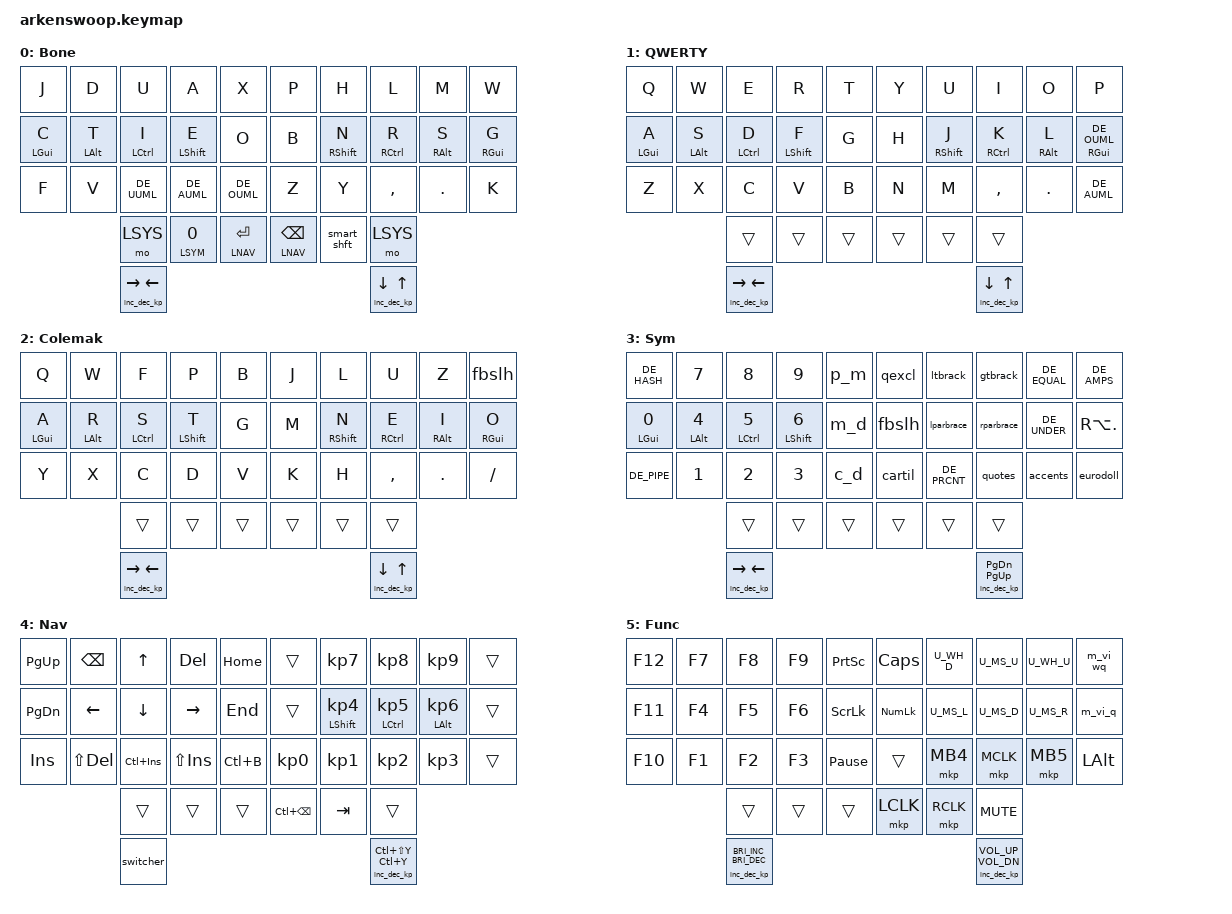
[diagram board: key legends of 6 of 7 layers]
/*
 * Copyright (c) 2023 The ZMK Contributors
 *
 * SPDX-License-Identifier: MIT
 */


#include <behaviors.dtsi>
#include "zmk-helpers/helper.h"
#include "zmk-helpers/key-labels/36.h"
#include <dt-bindings/zmk/keys.h>
#include <dt-bindings/zmk/ext_power.h>
#include <dt-bindings/zmk/outputs.h>
#include "keys_de.h"
#include <dt-bindings/zmk/bt.h>
#include <behaviors/num_word.dtsi>
#include "mouse.dtsi"
#include "arkenswoop_combos.dtsi"
#if __has_include("extras-arkenswoop.dtsi")
#include "extras-arkenswoop.dtsi"
#endif

#define ________ &trans
#define __XXXX__ &none

#define DE_AUML DE_A_UMLAUT
#define DE_OUML DE_O_UMLAUT
#define DE_UUML DE_U_UMLAUT

#define LBONE 0
#define LQWERTY 1 
#define LCOLMK 2
#define LSYM 3
#define LNAV 4
#define LFN  5
#define LSYS 6


/* Global settings */

#define QUICK_TAP_MS 175

&sk {  // sticky-key config
    release-after-ms = <900>;  // release after 0.9s
    quick-release;             // no double capitalization when rolling keys
};

&sl {  // sticky-layer config
    ignore-modifiers;          // allow chording sticky mods & layers
};

&lt {  // layer-tap config
    flavor = "balanced";
    tapping-term-ms = <200>;
    quick-tap-ms = <QUICK_TAP_MS>;
};

&key_repeat {
    usage-pages = <HID_USAGE_KEY HID_USAGE_CONSUMER>;
};


/* Homerow mods */

#define KEYS_L LT0 LT1 LT2 LT3 LT4 LM0 LM1 LM2 LM3 LM4 LB0 LB1 LB2 LB3 LB4 // left hand
#define KEYS_R RT0 RT1 RT2 RT3 RT4 RM0 RM1 RM2 RM3 RM4 RB0 RB1 RB2 RB3 RB4 // right hand
#define THUMBS LH2 LH1 LH0 RH0 RH1 RH2                // thumbs

#define MAKE_HRM(NAME, HOLD, TAP, TRIGGER_POS) \
    ZMK_BEHAVIOR(NAME, hold_tap, \
        flavor = "balanced"; \
        tapping-term-ms = <280>; \
        quick-tap-ms = <QUICK_TAP_MS>; \
        require-prior-idle-ms = <200>; \
        bindings = <HOLD>, <TAP>; \
        hold-trigger-key-positions = <TRIGGER_POS>; \
        hold-trigger-on-release; \
    )
MAKE_HRM(hml, &kp, &kp, KEYS_R THUMBS)  // left-hand HRMs
MAKE_HRM(hmr, &kp, &kp, KEYS_L THUMBS)  // right-hand HRMs



/* Caps-word, num-word and smart-mouse */

&caps_word {
    continue-list = <UNDERSCORE MINUS>;
};
// tap: sticky-shift | shift + tap/ double-tap: caps-word | hold: shift
ZMK_BEHAVIOR(smart_shft, mod_morph,
    bindings = <&sk LSHFT>, <&caps_word>;
    mods = <(MOD_LSFT)>;
)

// tap: space | shift + tap: dot -> space -> sticky shift | hold: activate layer
ZMK_BEHAVIOR(lt_spc, hold_tap,
    flavor = "balanced";
    tapping-term-ms = <200>;
    quick-tap-ms = <QUICK_TAP_MS>;
    bindings = <&mo>, <&spc_morph>;
)
ZMK_BEHAVIOR(spc_morph, mod_morph,
    bindings = <&kp SPACE>, <&dot_spc>;
    mods = <(MOD_LSFT|MOD_RSFT)>;
)
ZMK_BEHAVIOR(dot_spc, macro,
    wait-ms = <0>;
    tap-ms = <5>;
    bindings = <&kp DOT &kp SPACE &sk LSHFT>;
)

ZMK_TAP_DANCE(td_s,
    bindings = <&kp N1>, <&kp N2>, <&kp N3>;
)
// tap: num-word | double-tap: sticky num-layer | hold: num-layer

#define SMART_NUM &smart_num SYM 0
ZMK_BEHAVIOR(smart_num, hold_tap,
    flavor = "balanced";
    tapping-term-ms = <200>;
    quick-tap-ms = <QUICK_TAP_MS>;
    bindings = <&mo>, <&num_dance>;
)
ZMK_BEHAVIOR(num_dance, tap_dance,
    tapping-term-ms = <200>;
    bindings = <&num_word LSYM>, <&sl LSYM>;  // reverse this for sticky-num on single tap
)
&num_word {
    continue-list = <BSPC DEL DOT COMMA DE_PLUS DE_MINUS DE_STAR DE_FSLH LS(N0)>;
    ignore-modifiers;     
};


/* BLUETOOTH MACROS */
ZMK_BEHAVIOR(m_bt_sel, macro_one_param,
    wait-ms = <0>;
    tap-ms = <0>;
    bindings
      = <&macro_param_1to2>
      , <&bt BT_SEL MACRO_PLACEHOLDER>
      ;
)

ZMK_BEHAVIOR(m_bt_clr_prof, macro_one_param,
    wait-ms = <0>;
    tap-ms = <0>;
    bindings
      = <&macro_param_1to1>
      , <&m_bt_sel MACRO_PLACEHOLDER>
      , <&bt BT_CLR>
    ;
)

ZMK_BEHAVIOR(ht_btp, hold_tap,
    flavor = "tap-preferred";
    tapping-term-ms = <3000>;
    bindings = <&m_bt_clr_prof>,<&m_bt_sel>;
)

/* SYMBOLS */

// + or * (with SHFT)
ZMK_BEHAVIOR(p_m, mod_morph,
    bindings = <&kp DE_PLUS>, <&kp DE_STAR>;
    mods = <(MOD_LSFT|MOD_RSFT)>;
)

// - or / (with SHFT)
ZMK_BEHAVIOR(m_d, mod_morph,
    bindings = <&kp DE_MINUS>, <&kp DE_FSLH>;
    mods = <(MOD_LSFT|MOD_RSFT)>;
)
// , or . (with SHFT)
ZMK_BEHAVIOR(c_d, mod_morph,
    bindings = <&kp COMMA>, <&kp DOT>;
    mods = <(MOD_LSFT|MOD_RSFT)>;
)
// ( and { (with SHFT)
ZMK_BEHAVIOR(lparbrace, mod_morph,
    bindings = <&kp DE_LEFT_PARENTHESIS>, <&kp DE_LEFT_BRACE>;
    mods = <(MOD_LSFT|MOD_RSFT)>;
)
// ) and } (with SHFT)
ZMK_BEHAVIOR(rparbrace, mod_morph,
    bindings = <&kp DE_RIGHT_PARENTHESIS>, <&kp DE_RIGHT_BRACE>;
    mods = <(MOD_LSFT|MOD_RSFT)>;
)
// < and [ (with SHFT)
ZMK_BEHAVIOR(ltbrack, mod_morph,
    bindings = <&kp DE_LESS_THAN>, <&kp DE_LEFT_BRACKET>;
    mods = <(MOD_LSFT|MOD_RSFT)>;
)
// > and ] (with SHFT)
ZMK_BEHAVIOR(gtbrack, mod_morph,
    bindings = <&kp DE_GREATER_THAN>, <&kp DE_RIGHT_BRACKET>;
    mods = <(MOD_LSFT|MOD_RSFT)>;
)
// ' and " (with SHFT)
ZMK_BEHAVIOR(quotes, mod_morph,
    bindings = <&kp DE_SQT>, <&kp DE_DQT>;
    mods = <(MOD_LSFT|MOD_RSFT)>;
)
// ´ and ` (with SHFT)
ZMK_BEHAVIOR(accents, mod_morph,
    bindings = <&kp DE_ACUTE>, <&kp DE_GRAVE>;
    mods = <(MOD_LSFT|MOD_RSFT)>;
)
// ? and ! (with SHFT)
ZMK_BEHAVIOR(qexcl, mod_morph,
    bindings = <&kp DE_QMARK>, <&kp DE_EXCL>;
    mods = <(MOD_LSFT|MOD_RSFT)>;
)
// $ and € (with SHFT)
ZMK_BEHAVIOR(eurodoll, mod_morph,
    bindings = <&kp DE_DOLLAR>, <&kp DE_EURO>;
    mods = <(MOD_LSFT|MOD_RSFT)>;
)
// / and \ (with SHFT) 
ZMK_BEHAVIOR(fbslh, mod_morph,
    bindings = <&kp DE_FSLH>, <&kp DE_BSLH>;
    mods = <(MOD_LSFT|MOD_RSFT)>;
)
// ß and  (with SHFT)  
ZMK_BEHAVIOR(sz, mod_morph,
    bindings = <&kp DE_SZ>, <&kp DE_CAPITAL_SZ>;
    mods = <(MOD_LSFT|MOD_RSFT)>;
)
// ^ and ~ (with SHFT)  
ZMK_BEHAVIOR(cartil, mod_morph,
    bindings = <&kp DE_CARET>, <&kp DE_TILDE>;
    mods = <(MOD_LSFT|MOD_RSFT)>;
)

// Copy
// Ctrl+C or Ctrl+Ins  (with SHFT)  
ZMK_BEHAVIOR(copy, mod_morph,
    bindings = <&kp LC(C)>, <&kp LC(INS)>;
    mods = <(MOD_LSFT|MOD_RSFT)>;
)
// Paste
// Ctrl+V or Shft+Ins  (with SHFT)  
ZMK_BEHAVIOR(paste, mod_morph,
    bindings = <&kp LC(V)>, <&kp LS(INS)>;
    mods = <(MOD_LSFT|MOD_RSFT)>;
)


/* Switcher encoder */
/* Encoder switches windows */
/ {
    behaviors {
        switcher: switcher {
            compatible = "zmk,behavior-sensor-rotate";
            label = "ENCODER_SW";
            #sensor-binding-cells = <0>;
            bindings = <&alttab>, <&alttab_p>;
        };
};
};
ZMK_BEHAVIOR(alttab, tri_state, bindings = <&kp LALT>, <&kp TAB>, <&kt LALT>; )
ZMK_BEHAVIOR(alttab_p, tri_state, bindings = <&kp LALT>, <&kp LS(TAB)>, <&kt LALT>; )

ZMK_BEHAVIOR(m_vi_wq, macro, wait-ms = <50>; bindings = <&kp ESC &kp DE_COLON &kp W &kp Q>; )
ZMK_BEHAVIOR(m_vi_q, macro, wait-ms = <50>; bindings = <&kp ESC &kp DE_COLON &kp Q &kp DE_EXCL>; )


ZMK_CONDITIONAL_LAYER(fnlay, LSYM LNAV, LFN)

ZMK_LAYER(Bone,
    // ╭─────────────┬─────────────┬─────────────┬─────────────┬─────────────╮    ╭─────────────┬─────────────┬─────────────┬─────────────┬─────────────╮
         &kp J         &kp D         &kp U         &kp A         &kp X              &kp P         &kp H         &kp L         &kp M         &kp W       
    // ├─────────────┼─────────────┼─────────────┼─────────────┼─────────────┤    ├─────────────┼─────────────┼─────────────┼─────────────┼─────────────┤
         &hml LGUI C   &hml LALT T   &hml LCTRL I  &hml LSHFT E  &kp O              &kp B         &hmr RSHFT N  &hmr RCTRL R  &hmr RALT S   &hmr RGUI G 
    // ├─────────────┼─────────────┼───── ü ─────┼───── ä ─────┼───── ö ─────┤    ├─────────────┬─────────────┼─────────────┼─────────────┼─────────────┤
         &kp F         &kp V         &kp DE_UUML   &kp DE_AUML   &kp DE_OUML        &kp Z         &kp Y         &kp COMMA     &kp DOT       &kp K       
    // ╰─────────────┼─────────────┼─────────────┼─────────────┼─────────────┤    ├─────────────┬─────────────┼─────────────┼─────────────┼─────────────╯
                                     &mo LSYS      &lt_spc LSYM 0 &lt LNAV RET      &lt LNAV BSPC &smart_shft   &mo LSYS
    //                             ╰─────────────┴─────────────┴─────────────╯    ╰─────────────┴─────────────┴─────────────╯
    ,                            &inc_dec_kp RIGHT LEFT                                                     &inc_dec_kp DOWN UP                        
    //                                (       )                                                                  (       )
)

ZMK_LAYER(QWERTY,
    // ╭─────────────┬─────────────┬─────────────┬─────────────┬─────────────╮    ╭─────────────┬─────────────┬─────────────┬─────────────┬─────────────╮
         &kp Q         &kp W         &kp E         &kp R         &kp T              &kp Y         &kp U         &kp I         &kp O         &kp P       
    // ├─────────────┼─────────────┼─────────────┼─────────────┼─────────────┤    ├─────────────┼─────────────┼─────────────┼─────────────┼─────────────┤
         &hml LGUI A   &hml LALT S   &hml LCTRL D  &hml LSHFT F  &kp G              &kp H         &hmr RSHFT J  &hmr RCTRL K  &hmr RALT L   &hmr RGUI DE_OUML 
    // ├─────────────┼─────────────┼───── ü ─────┼───── ä ─────┼───── ö ─────┤    ├─────────────┬─────────────┼─────────────┼─────────────┼─────────────┤
         &kp Z         &kp X         &kp C         &kp V         &kp B              &kp N         &kp M         &kp COMMA     &kp DOT       &kp DE_AUML       
    // ╰─────────────┼─────────────┼─────────────┼─────────────┼─────────────┤    ├─────────────┬─────────────┼─────────────┼─────────────┼─────────────╯
                                      ________      ________      ________           ________      ________      ________   
    //                             ╰─────────────┴─────────────┴─────────────╯    ╰─────────────┴─────────────┴─────────────╯
    ,                            &inc_dec_kp RIGHT LEFT                                                     &inc_dec_kp DOWN UP                        
    //                                (       )                                                                  (       )
)

ZMK_LAYER(Colemak,
    // ╭─────────────┬─────────────┬─────────────┬─────────────┬─────────────╮    ╭─────────────┬─────────────┬─────────────┬─────────────┬─────────────╮
         &kp Q         &kp W         &kp F         &kp P         &kp B              &kp J         &kp L         &kp U         &kp Z         &fbslh      
    // ├─────────────┼─────────────┼─────────────┼─────────────┼─────────────┤    ├─────────────┼─────────────┼─────────────┼─────────────┼─────────────┤
         &hml LGUI A   &hml LALT R   &hml LCTRL S  &hml LSHFT T  &kp G              &kp M         &hmr RSHFT N  &hmr RCTRL E  &hmr RALT I   &hmr RGUI O 
    // ├─────────────┼─────────────┼─────────────┼─────────────┼─────────────┤    ├─────────────┬─────────────┼─────────────┼─────────────┼─────────────┤
         &kp Y         &kp X         &kp C         &kp D         &kp V              &kp K         &kp H         &kp COMMA     &kp DOT       &kp SLASH       
    // ╰─────────────┼─────────────┼─────────────┼─────────────┼─────────────┤    ├─────────────┬─────────────┼─────────────┼─────────────┼─────────────╯
                                      ________      ________      ________           ________     ________       ________   
    //                             ╰─────────────┴─────────────┴─────────────╯    ╰─────────────┴─────────────┴─────────────╯
    ,                            &inc_dec_kp RIGHT LEFT                                                     &inc_dec_kp DOWN UP                        
    //                                (       )                                                                  (       )
)

ZMK_LAYER(Sym,
    // ╭────── # ────┬─────────────┬─────────────┬─────────────┬──── + * ────╮    ╭──── ? ! ────┬──── < [ ────┬──── > ] ────┬───── = ─────┬───── & ─────╮
         &kp DE_HASH   &kp N7        &kp N8        &kp N9        &p_m               &qexcl        &ltbrack      &gtbrack      &kp DE_EQUAL  &kp DE_AMPS   
    // ├─────────────┼─────────────┼─────────────┼─────────────┼──── - / ────┤    ├──── / \ ────┼──── ( { ────┼──── ) } ────┼───── _ ─────┼───── … ─────┤
         &hml LGUI N0  &hml LALT N4  &hml LCTRL N5 &hml LSHFT N6 &m_d               &fbslh        &lparbrace    &rparbrace    &kp DE_UNDER  &kp RA(DOT) 
    // ├────── | ────┼─────────────┼─────────────┼─────────────┼──── , . ────┤    ├──── ^ ~ ────┼───── % ─────┼──── ' " ────┼──── ´ ` ────┼──── € $ ────┤
         &kp DE_PIPE   &kp N1        &kp N2        &kp N3        &c_d               &cartil       &kp DE_PRCNT  &quotes       &accents      &eurodoll     
    // ╰─────────────┼─────────────┼─────────────┼─────────────┼─────────────┤    ├─────────────┼─────────────┼─────────────┼─────────────┼─────────────┤
                                      ________      ________      ________           ________      ________      ________   
    //                             ╰─────────────┴─────────────┴─────────────╯    ╰─────────────┴─────────────┴─────────────╯
    ,                            &inc_dec_kp RIGHT LEFT                                                 &inc_dec_kp PAGE_DOWN PAGE_UP                    
    //                                (       )                                                                  (       )
)

ZMK_LAYER(Nav,
    // ╭─────────────┬─────────────┬─────────────┬─────────────┬─────────────╮    ╭─────────────┬─────────────┬─────────────┬─────────────┬─────────────╮
         &kp PG_UP     &kp BSPC      &kp UP        &kp DEL       &kp HOME            ________     &kp KP_N7     &kp KP_N8     &kp KP_N9      ________   
    // ├─────────────┼─────────────┼─────────────┼─────────────┼─────────────┤    ├─────────────┼─────────────┼─────────────┼─────────────┼─────────────┤
         &kp PG_DN     &kp LEFT      &kp DOWN      &kp RIGHT     &kp END             ________ &hmr LSHFT KP_N4 &hmr LCTRL KP_N5 &hmr LALT KP_N6 ________   
    // ├─────────────┼─────────────┼─────────────┼─────────────┼─────────────┤    ├─────────────┼─────────────┼─────────────┼─────────────┼─────────────┤
         &kp INS       &kp LS(DEL)   &kp LC(INS)   &kp LS(INS)   &kp LC(B)          &kp KP_N0     &kp KP_N1     &kp KP_N2     &kp KP_N3      ________   
    // ╰─────────────┼─────────────┼─────────────┼─────────────┼─────────────┤    ├─────────────┼─────────────┼─────────────┼─────────────┼─────────────┤
                                      ________      ________      ________          &kp LC(BKSP)  &kp TAB        ________  
    //                             ╰─────────────┴─────────────┴─────────────╯    ╰─────────────┴─────────────┴─────────────╯
    ,                                 &switcher                                                   &inc_dec_kp LC(LS(Y)) LC(Y)  //<-UNDO REDO->                      
    //                                (       )                                                                  (       )
)

ZMK_LAYER(Func,
    // ╭─────────────┬─────────────┬─────────────┬─────────────┬─────────────╮    ╭─────────────┬─────────────┬─────────────┬─────────────┬─────────────╮
         &kp F12       &kp F7        &kp F8        &kp F9        &kp PSCRN           &kp CAPS      U_WH_D        U_MS_U        U_WH_U       &m_vi_wq   
    // ├─────────────┼─────────────┼─────────────┼─────────────┼─────────────┤    ├─────────────┼─────────────┼─────────────┼─────────────┼─────────────┤
         &kp F11       &kp F4        &kp F5        &kp F6        &kp SLCK            &kp KP_NUM    U_MS_L        U_MS_D        U_MS_R       &m_vi_q   
    // ├─────────────┼─────────────┼─────────────┼─────────────┼─────────────┤    ├─────────────┼─────────────┼─────────────┼─────────────┼─────────────┤
         &kp F10       &kp F1        &kp F2        &kp F3        &kp PAUSE_BREAK     ________      &mkp MB4      &mkp MCLK     &mkp MB5     &kp LALT   
    // ╰─────────────┼─────────────┼─────────────┼─────────────┼─────────────┤    ├─────────────┼─────────────┼─────────────┼─────────────┼─────────────┤
                                      ________      ________      ________           &mkp LCLK     &mkp RCLK     &kp K_MUTE  
    //                             ╰─────────────┴─────────────┴─────────────╯    ╰─────────────┴─────────────┴─────────────╯
    ,                             &inc_dec_kp C_BRI_INC C_BRI_DEC                                                 &inc_dec_kp K_VOL_UP K_VOL_DN                       
    //                                (       )                                                                 (       )
)

ZMK_LAYER(SYS,
    // ╭─────────────┬─────────────┬─────────────┬─────────────┬─────────────╮    ╭─────────────┬─────────────┬─────────────┬─────────────┬─────────────╮
         &ht_btp 0 0   &ht_btp 1 1   &ht_btp 2 2   &ht_btp 3 3   &ht_btp 4 4        &to LBONE     &to LQWERTY    &to LCOLMK    ________      ________   
    // ├─────────────┼─────────────┼─────────────┼─────────────┼─────────────┤    ├─────────────┼─────────────┼─────────────┼─────────────┼─────────────┤
         &out OUT_TOG   ________      ________      ________     &bootloader        &bootloader    ________      ________      ________      ________   
    // ├─────────────┼─────────────┼─────────────┼─────────────┼─────────────┤    ├─────────────┼─────────────┼─────────────┼─────────────┼─────────────┤
         &kp C_SLEEP   &kp K_SLEEP   &kp C_POWER   &kp K_POWER   &sys_reset         &sys_reset     ________      ________      ________      ________     
    // ╰─────────────┼─────────────┼─────────────┼─────────────┼─────────────┤    ├─────────────┼─────────────┼─────────────┼─────────────┼─────────────┤
                                      ________      ________      ________           ________      ________      ________  
    //                             ╰─────────────┴─────────────┴─────────────╯    ╰─────────────┴─────────────┴─────────────╯
    //,                                 &none                                                                   &none                  
    //                                (       )                                                                  (       )
)

